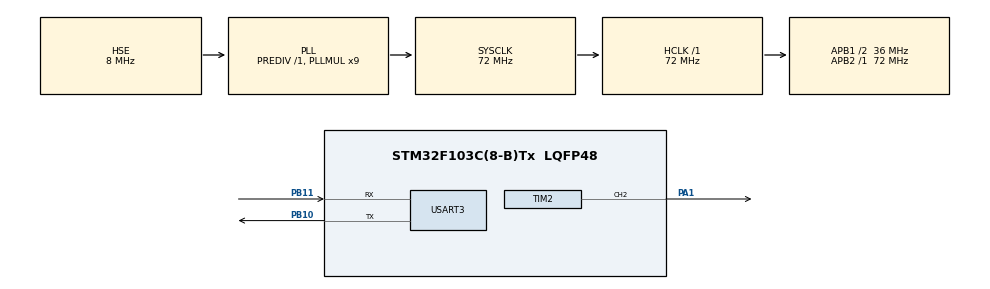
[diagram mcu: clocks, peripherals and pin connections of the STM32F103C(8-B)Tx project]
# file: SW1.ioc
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Mcu.Family=STM32F1
Mcu.Name=STM32F103C(8-B)Tx
Mcu.Package=LQFP48
NVIC.PriorityGroup=NVIC_PRIORITYGROUP_4
NVIC.USART3_IRQn=true\:0\:0\:false\:false\:true\:true\:true\:true
PA1.Signal=S_TIM2_CH2
PB10.Mode=Asynchronous
PB10.Signal=USART3_TX
PB11.Mode=Asynchronous
PB11.Signal=USART3_RX
PD0-OSC_IN.Mode=HSE-External-Oscillator
PD0-OSC_IN.Signal=RCC_OSC_IN
PD1-OSC_OUT.Mode=HSE-External-Oscillator
PD1-OSC_OUT.Signal=RCC_OSC_OUT
ProjectManager.HeapSize=0x200
ProjectManager.StackSize=0x400
ProjectManager.TargetToolchain=MDK-ARM V5.32
RCC.AHBFreq_Value=72000000
RCC.APB1CLKDivider=RCC_HCLK_DIV2
RCC.APB1Freq_Value=36000000
RCC.APB1TimFreq_Value=72000000
RCC.APB2Freq_Value=72000000
RCC.APB2TimFreq_Value=72000000
RCC.HCLKFreq_Value=72000000
RCC.PLLMUL=RCC_PLL_MUL9
RCC.PLLSourceVirtual=RCC_PLLSOURCE_HSE
RCC.SYSCLKFreq_VALUE=72000000
RCC.SYSCLKSource=RCC_SYSCLKSOURCE_PLLCLK
RCC.USBFreq_Value=72000000
SH.S_TIM2_CH2.0=TIM2_CH2,PWM Generation2 CH2
TIM2.Channel-PWM\ Generation2\ CH2=TIM_CHANNEL_2
USART3.VirtualMode=VM_ASYNC
VP_SYS_VS_ND.Mode=No_Debug
VP_TIM2_VS_ClockSourceINT.Mode=Internal
board=custom

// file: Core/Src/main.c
/* USER CODE BEGIN Header */
/**
  ******************************************************************************
  * @file           : main.c
  * @brief          : Main program body
  ******************************************************************************
  * @attention
  *
  * Copyright (c) 2026 STMicroelectronics.
  * All rights reserved.
  *
  * This software is licensed under terms that can be found in the LICENSE file
  * in the root directory of this software component.
  * If no LICENSE file comes with this software, it is provided AS-IS.
  *
  ******************************************************************************
  */
/* USER CODE END Header */
#include "main.h"
/* USER CODE BEGIN Includes */
#include "stdio.h"
#include "string.h"
#include "stdlib.h"
/* USER CODE END Includes */

/* USER CODE BEGIN PTD */
#define CH_COUNT 2
typedef struct
{
    float fdata[CH_COUNT];
    unsigned char tail[4];
} Frame;
/* USER CODE END PTD */

TIM_HandleTypeDef htim2;
UART_HandleTypeDef huart3;

void SystemClock_Config(void);
static void MX_GPIO_Init(void);
static void MX_USART3_UART_Init(void);
static void MX_TIM2_Init(void);
/* USER CODE BEGIN PFP */
static const uint8_t FRAME_TAIL[4] = {0x00, 0x00, 0x80, 0x7f};
/* USER CODE END PFP */

/* USER CODE BEGIN 0 */
float angle,CCR;
uint8_t rx_buf[20]; //接收数据缓冲区

/**
  * @brief  设置捕获比较寄存器的值
  * @param  无
  * @retval 无
  */
void Set_CCR(void)
{
  CCR = 500.0f + angle * (2000.0f / 180.0f);
  TIM2->CCR2 =  CCR;
}

/**
  * @brief  获取占空比
  * @param  无
  * @retval 返回占空比
  */
float Get_Duty(void)
{
  float Duty;
  Duty = CCR / TIM2->ARR;
  return Duty;
}

/**
  * @brief  发送浮点数数据
  * @param  无
  * @retval 无
  */
void Send_JustFloat(void)
{
    Frame frame_data;
    frame_data.fdata[0] = angle;
    frame_data.fdata[1] = Get_Duty();
    //拷贝帧尾
    memcpy(frame_data.tail, FRAME_TAIL, 4);
    HAL_UART_Transmit(&huart3, (uint8_t *)&frame_data, sizeof(Frame), 10);
}

//接收数据回调函数
void HAL_UARTEx_RxEventCallback(UART_HandleTypeDef *huart, uint16_t Size)
{
  if(huart->Instance == USART3)
  {
    rx_buf[Size] = '\0';
    angle = atof((char*)rx_buf);  //将接收到的字符串转换为浮点数
    angle = angle < 0 ? 0 : angle;
    angle = angle > 180 ? 180 : angle;
    Set_CCR();

    HAL_UARTEx_ReceiveToIdle_IT(&huart3, rx_buf, 20); //
    memset(rx_buf,0,20);
  }
}

/* USER CODE END 0 */

int main(void)
{

  /* MCU Configuration--------------------------------------------------------*/

  /* Reset of all peripherals, Initializes the Flash interface and the Systick. */
  HAL_Init();

  /* Configure the system clock */
  SystemClock_Config();

  /* Initialize all configured peripherals */
  MX_GPIO_Init();
  MX_USART3_UART_Init();
  MX_TIM2_Init();
  /* USER CODE BEGIN 2 */
  HAL_TIM_PWM_Start(&htim2, TIM_CHANNEL_2);
  HAL_UARTEx_ReceiveToIdle_IT(&huart3, rx_buf, 20);
  /* USER CODE END 2 */

  /* Infinite loop */
  while (1)
  {

    /* USER CODE BEGIN 3 */
    HAL_Delay(1000);
    Send_JustFloat();
  }
  /* USER CODE END 3 */
}

void SystemClock_Config(void)
{
  RCC_OscInitTypeDef RCC_OscInitStruct = {0};
  RCC_ClkInitTypeDef RCC_ClkInitStruct = {0};

  /** Initializes the RCC Oscillators according to the specified parameters
  * in the RCC_OscInitTypeDef structure.
  */
  RCC_OscInitStruct.OscillatorType = RCC_OSCILLATORTYPE_HSE;
  RCC_OscInitStruct.HSEState = RCC_HSE_ON;
  RCC_OscInitStruct.HSEPredivValue = RCC_HSE_PREDIV_DIV1;
  RCC_OscInitStruct.HSIState = RCC_HSI_ON;
  RCC_OscInitStruct.PLL.PLLState = RCC_PLL_ON;
  RCC_OscInitStruct.PLL.PLLSource = RCC_PLLSOURCE_HSE;
  RCC_OscInitStruct.PLL.PLLMUL = RCC_PLL_MUL9;
  if (HAL_RCC_OscConfig(&RCC_OscInitStruct) != HAL_OK)
  {
    Error_Handler();
  }

  /** Initializes the CPU, AHB and APB buses clocks
  */
  RCC_ClkInitStruct.ClockType = RCC_CLOCKTYPE_HCLK|RCC_CLOCKTYPE_SYSCLK
                              |RCC_CLOCKTYPE_PCLK1|RCC_CLOCKTYPE_PCLK2;
  RCC_ClkInitStruct.SYSCLKSource = RCC_SYSCLKSOURCE_PLLCLK;
  RCC_ClkInitStruct.AHBCLKDivider = RCC_SYSCLK_DIV1;
  RCC_ClkInitStruct.APB1CLKDivider = RCC_HCLK_DIV2;
  RCC_ClkInitStruct.APB2CLKDivider = RCC_HCLK_DIV1;

  if (HAL_RCC_ClockConfig(&RCC_ClkInitStruct, FLASH_LATENCY_2) != HAL_OK)
  {
    Error_Handler();
  }
}

static void MX_TIM2_Init(void)
{

  TIM_ClockConfigTypeDef sClockSourceConfig = {0};
  TIM_MasterConfigTypeDef sMasterConfig = {0};
  TIM_OC_InitTypeDef sConfigOC = {0};

  htim2.Instance = TIM2;
  htim2.Init.Prescaler = 72 - 1;
  htim2.Init.CounterMode = TIM_COUNTERMODE_UP;
  htim2.Init.Period = 20000 - 1;
  htim2.Init.ClockDivision = TIM_CLOCKDIVISION_DIV1;
  htim2.Init.AutoReloadPreload = TIM_AUTORELOAD_PRELOAD_DISABLE;
  if (HAL_TIM_Base_Init(&htim2) != HAL_OK)
  {
    Error_Handler();
  }
  sClockSourceConfig.ClockSource = TIM_CLOCKSOURCE_INTERNAL;
  if (HAL_TIM_ConfigClockSource(&htim2, &sClockSourceConfig) != HAL_OK)
  {
    Error_Handler();
  }
  if (HAL_TIM_PWM_Init(&htim2) != HAL_OK)
  {
    Error_Handler();
  }
  sMasterConfig.MasterOutputTrigger = TIM_TRGO_RESET;
  sMasterConfig.MasterSlaveMode = TIM_MASTERSLAVEMODE_DISABLE;
  if (HAL_TIMEx_MasterConfigSynchronization(&htim2, &sMasterConfig) != HAL_OK)
  {
    Error_Handler();
  }
  sConfigOC.OCMode = TIM_OCMODE_PWM1;
  sConfigOC.Pulse = 500;
  sConfigOC.OCPolarity = TIM_OCPOLARITY_HIGH;
  sConfigOC.OCFastMode = TIM_OCFAST_DISABLE;
  if (HAL_TIM_PWM_ConfigChannel(&htim2, &sConfigOC, TIM_CHANNEL_2) != HAL_OK)
  {
    Error_Handler();
  }
  HAL_TIM_MspPostInit(&htim2);

}

static void MX_USART3_UART_Init(void)
{

  huart3.Instance = USART3;
  huart3.Init.BaudRate = 115200;
  huart3.Init.WordLength = UART_WORDLENGTH_8B;
  huart3.Init.StopBits = UART_STOPBITS_1;
  huart3.Init.Parity = UART_PARITY_NONE;
  huart3.Init.Mode = UART_MODE_TX_RX;
  huart3.Init.HwFlowCtl = UART_HWCONTROL_NONE;
  huart3.Init.OverSampling = UART_OVERSAMPLING_16;
  if (HAL_UART_Init(&huart3) != HAL_OK)
  {
    Error_Handler();
  }

}

static void MX_GPIO_Init(void)
{

  /* GPIO Ports Clock Enable */
  __HAL_RCC_GPIOD_CLK_ENABLE();
  __HAL_RCC_GPIOA_CLK_ENABLE();
  __HAL_RCC_GPIOB_CLK_ENABLE();

}

void Error_Handler(void)
{
  __disable_irq();
  while (1)
  {
  }
}
